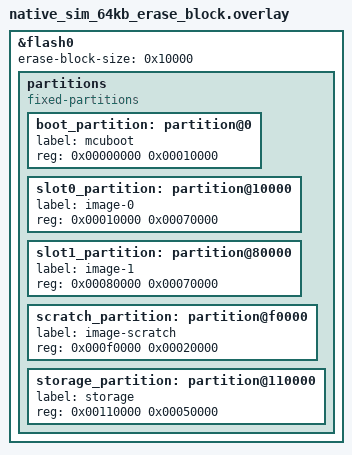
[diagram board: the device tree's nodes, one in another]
/*
 * Copyright (c) 2025 Google LLC
 *
 * SPDX-License-Identifier: Apache-2.0
 */

&flash0 {
	erase-block-size = <0x10000>;

	/*
	 * Delete old partitions that were not aligned on 64kb addresses and
	 * create new ones that are aligned.
	 */
	/delete-node/ partitions;
	partitions {
		compatible = "fixed-partitions";
		#address-cells = <1>;
		#size-cells = <1>;

		boot_partition: partition@0 {
			label = "mcuboot";
			reg = <0x00000000 0x00010000>;
		};
		slot0_partition: partition@10000 {
			label = "image-0";
			reg = <0x00010000 0x00070000>;
		};
		slot1_partition: partition@80000 {
			label = "image-1";
			reg = <0x00080000 0x00070000>;
		};
		scratch_partition: partition@f0000 {
			label = "image-scratch";
			reg = <0x000f0000 0x00020000>;
		};
		storage_partition: partition@110000 {
			label = "storage";
			reg = <0x00110000 0x00050000>;
		};
	};
};
